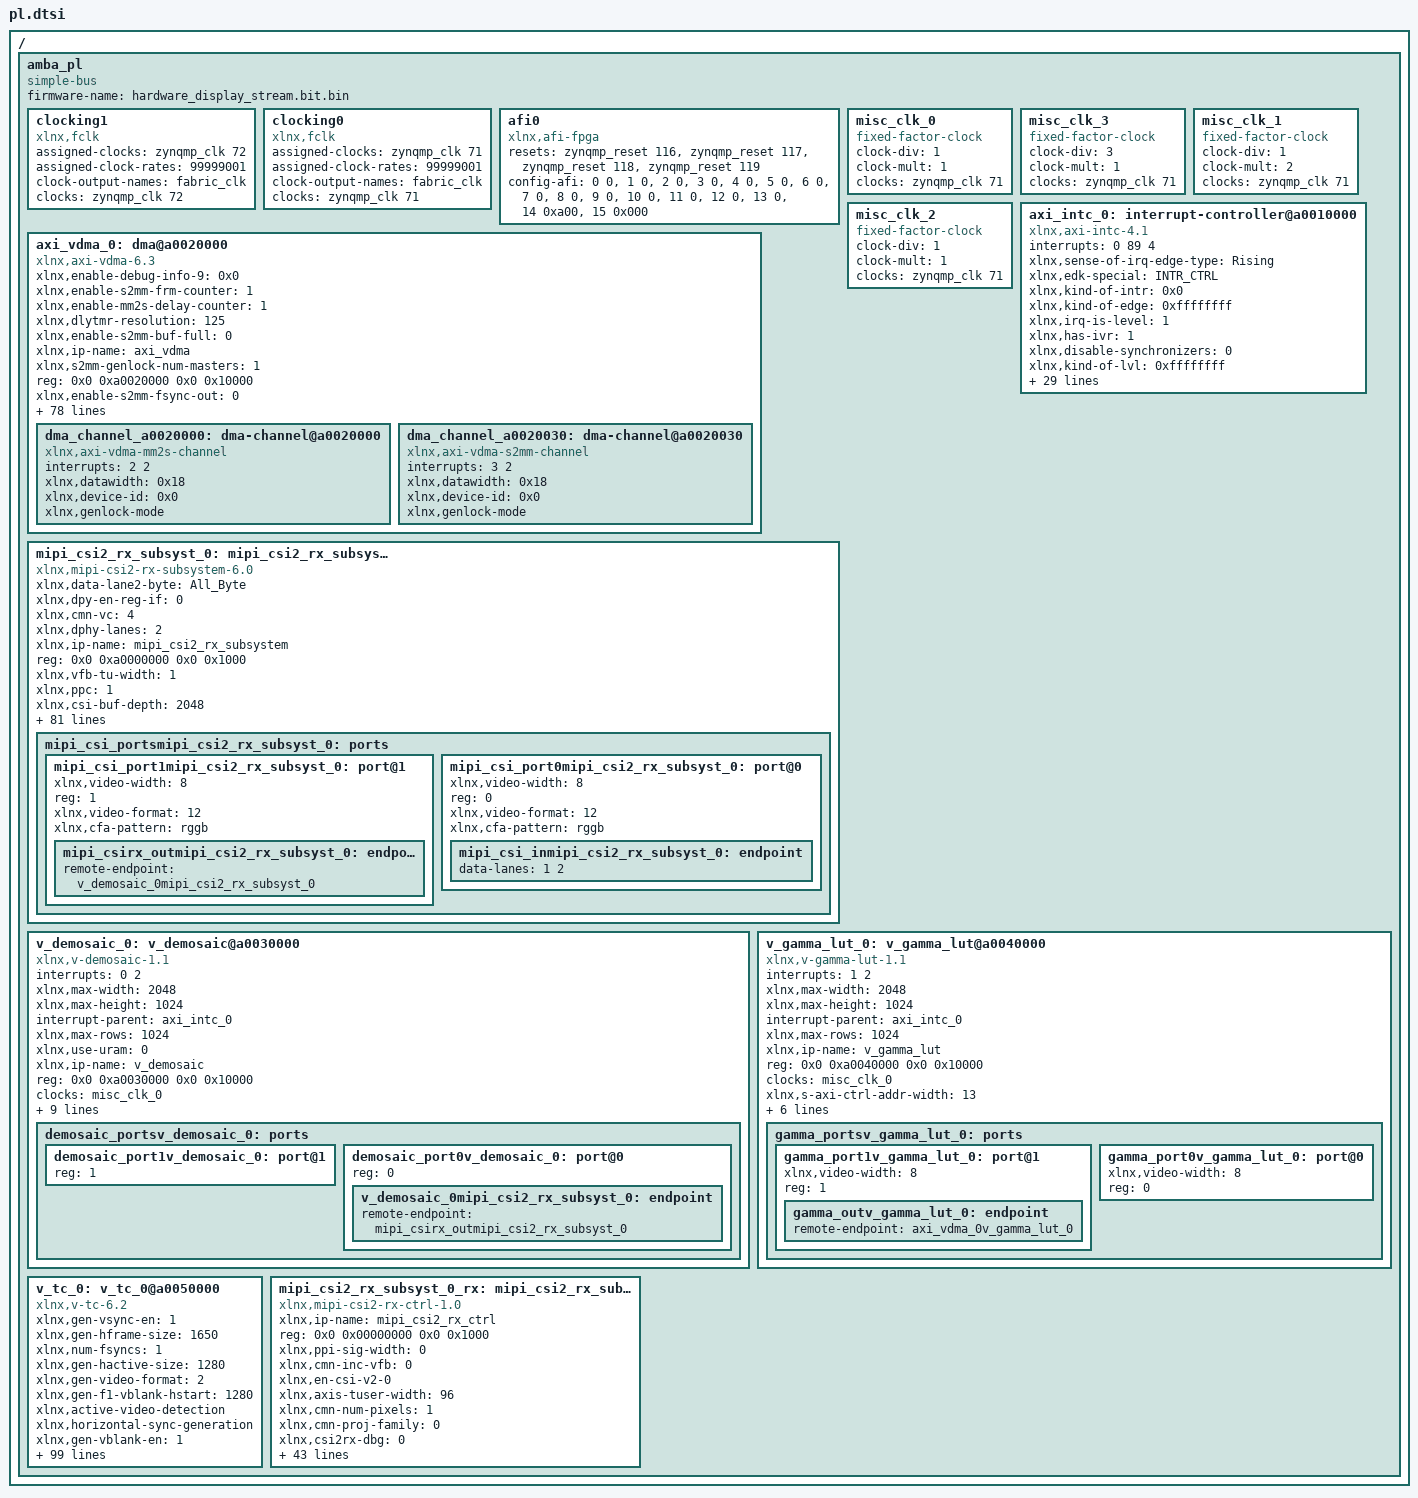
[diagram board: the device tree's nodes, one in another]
/ {
	amba_pl: amba_pl {
		ranges;
		compatible = "simple-bus";
		#address-cells = <2>;
		#size-cells = <2>;
		firmware-name = "hardware_display_stream.bit.bin";
		clocking1: clocking1 {
			compatible = "xlnx,fclk";
			status = "okay";
			assigned-clocks = <&zynqmp_clk 72>;
			assigned-clock-rates = <99999001>;
			#clock-cells = <0>;
			clock-output-names = "fabric_clk";
			clocks = <&zynqmp_clk 72>;
		};
		clocking0: clocking0 {
			compatible = "xlnx,fclk";
			status = "okay";
			assigned-clocks = <&zynqmp_clk 71>;
			assigned-clock-rates = <99999001>;
			#clock-cells = <0>;
			clock-output-names = "fabric_clk";
			clocks = <&zynqmp_clk 71>;
		};
		afi0: afi0 {
			status = "okay";
			compatible = "xlnx,afi-fpga";
			resets = <&zynqmp_reset 116>, <&zynqmp_reset 117>, <&zynqmp_reset 118>, <&zynqmp_reset 119>;
			config-afi = < 0 0>, <1 0>, <2 0>, <3 0>, <4 0>, <5 0>, <6 0>, <7 0>, <8 0>, <9 0>, <10 0>, <11 0>, <12 0>, <13 0>, <14 0xa00>, <15 0x000>;
		};
		misc_clk_0: misc_clk_0 {
			clock-div = <1>;
			compatible = "fixed-factor-clock";
			clock-mult = <1>;
			clocks = <&zynqmp_clk 71>;
			#clock-cells = <0>;
		};
		misc_clk_3: misc_clk_3 {
			clock-div = <3>;
			compatible = "fixed-factor-clock";
			clock-mult = <1>;
			clocks = <&zynqmp_clk 71>;
			#clock-cells = <0>;
		};
		misc_clk_1: misc_clk_1 {
			clock-div = <1>;
			compatible = "fixed-factor-clock";
			clock-mult = <2>;
			clocks = <&zynqmp_clk 71>;
			#clock-cells = <0>;
		};
		misc_clk_2: misc_clk_2 {
			clock-div = <1>;
			compatible = "fixed-factor-clock";
			clock-mult = <1>;
			clocks = <&zynqmp_clk 71>;
			#clock-cells = <0>;
		};
		axi_intc_0: interrupt-controller@a0010000 {
			#interrupt-cells = <2>;
			interrupts = < 0 89 4 >;
			xlnx,sense-of-irq-edge-type = "Rising";
			xlnx,edk-special = "INTR_CTRL";
			xlnx,kind-of-intr = <0x0>;
			xlnx,kind-of-edge = <0xffffffff>;
			xlnx,irq-is-level = <1>;
			xlnx,has-ivr = <1>;
			compatible = "xlnx,axi-intc-4.1" , "xlnx,xps-intc-1.00.a";
			xlnx,disable-synchronizers = <0>;
			xlnx,kind-of-lvl = <0xffffffff>;
			xlnx,ivar-reset-value = <0x10>;
			xlnx,irq-active = <0x1>;
			interrupt-parent = <&imux>;
			xlnx,en-cascade-mode = <0>;
			xlnx,ip-name = "axi_intc";
			xlnx,has-ilr = <0>;
			reg = <0x0 0xa0010000 0x0 0x10000>;
			xlnx,addr-width = <0x20>;
			clocks = <&misc_clk_0>;
			xlnx,s-axi-aclk-freq-mhz = <0x8f0cba4>;
			xlnx,num-sw-intr = <0>;
			xlnx,irq-connection = <1>;
			xlnx,num-intr-inputs = <0x4>;
			xlnx,has-sie = <1>;
			xlnx,enable-async = <0>;
			xlnx,has-cie = <1>;
			xlnx,num-sync-ff = <2>;
			xlnx,edk-iptype = "PERIPHERAL";
			xlnx,mb-clk-not-connected = <1>;
			xlnx,has-ipr = <1>;
			xlnx,sense-of-irq-level-type = "Active_High";
			xlnx,cascade-master = <0>;
			xlnx,processor-clk-freq-mhz = <100>;
			status = "okay";
			xlnx,is-fast = <0x0>;
			clock-names = "s_axi_aclk";
			xlnx,has-fast = <0>;
			xlnx,ivar-rst-val = <0x10>;
			interrupt-controller;
			interrupt-names = "irq";
			xlnx,async-intr = <0xfffffff0>;
			xlnx,name = "axi_intc_0";
		};
		axi_vdma_0: dma@a0020000 {
			xlnx,enable-debug-info-9 = <0x0>;
			xlnx,enable-s2mm-frm-counter = <1>;
			xlnx,enable-mm2s-delay-counter = <1>;
			xlnx,dlytmr-resolution = <125>;
			xlnx,enable-s2mm-buf-full = <0>;
			xlnx,ip-name = "axi_vdma";
			xlnx,s2mm-genlock-num-masters = <1>;
			reg = <0x0 0xa0020000 0x0 0x10000>;
			xlnx,enable-s2mm-fsync-out = <0>;
			xlnx,use-mm2s-fsync = <0>;
			xlnx,s2mm-linebuffer-thresh = <4>;
			xlnx,enable-mm2s-frm-counter = <1>;
			xlnx,m-axis-mm2s-tdata-width = <24>;
			xlnx,enable-all = <0>;
			xlnx,dynamic-resolution = <1>;
			xlnx,enable-s2mm-rst-out = <0>;
			interrupt-names = "mm2s_introut" , "s2mm_introut";
			xlnx,s2mm-sof-enable = <0x1>;
			xlnx,mm2s-genlock-num-masters = <1>;
			xlnx,enable-mm2s-fsync-out = <0>;
			xlnx,mm2s-linebuffer-thresh = <4>;
			compatible = "xlnx,axi-vdma-6.3" , "xlnx,axi-vdma-1.00.a";
			xlnx,enable-tstvec = <0>;
			interrupt-parent = <&axi_intc_0>;
			xlnx,s2mm-max-burst-length = <8>;
			xlnx,enable-mm2s-rst-out = <0>;
			xlnx,mm2s-sof-enable = <1>;
			xlnx,include-s2mm-dre = <0x0>;
			xlnx,enable-s2mm-frmstr-reg = <0>;
			xlnx,m-axi-s2mm-data-width = <64>;
			xlnx,enable-s2mm-sts-reg = <0>;
			xlnx,mm2s-max-burst-length = <8>;
			status = "okay";
			xlnx,include-mm2s-dre = <0x0>;
			xlnx,name = "axi_vdma_0";
			xlnx,enable-mm2s-frmstr-reg = <0>;
			interrupts = < 2 2 3 2 >;
			xlnx,m-axi-mm2s-data-width = <64>;
			xlnx,flush-on-fsync = <0x1>;
			xlnx,include-s2mm-sf = <1>;
			xlnx,single-interface = <0>;
			xlnx,s2mm-linebuffer-depth = <0x200>;
			xlnx,include-s2mm = <0x1>;
			xlnx,addr-width = <32>;
			clocks = <&misc_clk_0>, <&misc_clk_0>, <&misc_clk_0>, <&misc_clk_0>, <&misc_clk_0>;
			xlnx,s-axis-s2mm-tdata-width = <24>;
			xlnx,enable-debug-info-10 = <0>;
			xlnx,addrwidth = <0x20>;
			xlnx,enable-debug-info-11 = <0>;
			xlnx,edk-iptype = "PERIPHERAL";
			xlnx,enable-debug-info-12 = <0>;
			xlnx,use-fsync = <1>;
			xlnx,s2mm-genlock-repeat-en = <1>;
			xlnx,enable-debug-info-13 = <0x0>;
			xlnx,enable-vert-flip = <0x0>;
			xlnx,include-mm2s-sf = <0>;
			xlnx,enable-debug-info-14 = <0x1>;
			xlnx,include-internal-genlock = <0x1>;
			clock-names = "m_axi_mm2s_aclk" , "m_axi_s2mm_aclk" , "m_axis_mm2s_aclk" , "s_axi_lite_aclk" , "s_axis_s2mm_aclk";
			xlnx,enable-debug-info-15 = <0x1>;
			xlnx,mm2s-linebuffer-depth = <0x200>;
			xlnx,include-mm2s = <0x1>;
			xlnx,s2mm-genlock-mode = <0x2>;
			xlnx,flush-fsync = <0x1>;
			xlnx,select-xpm = <0>;
			xlnx,s2mm-data-width = <0x40>;
			xlnx,num-fstores = <0x4>;
			xlnx,enable-s2mm-param-updt = <0>;
			xlnx,enable-vidparam-reads = <0x1>;
			xlnx,mm2s-genlock-repeat-en = <0>;
			xlnx,prmry-is-aclk-async = <0>;
			xlnx,s2mm-tdata-width = <0x18>;
			#dma-cells = <1>;
			xlnx,enable-vidprmtr-reads = <1>;
			xlnx,mm2s-genlock-mode = <0x3>;
			xlnx,enable-debug-info-0 = <0>;
			xlnx,enable-debug-all = <0x0>;
			xlnx,enable-debug-info-1 = <0x0>;
			xlnx,mm2s-data-width = <0x40>;
			xlnx,enable-debug-info-2 = <0>;
			xlnx,enable-mm2s-param-updt = <0>;
			xlnx,enable-debug-info-3 = <0>;
			xlnx,enable-s2mm-delay-counter = <1>;
			xlnx,enable-debug-info-4 = <0>;
			xlnx,enable-debug-info-5 = <0x0>;
			xlnx,mm2s-tdata-width = <0x18>;
			xlnx,enable-debug-info-6 = <0x1>;
			xlnx,enable-debug-info-7 = <0x1>;
			xlnx,use-s2mm-fsync = <2>;
			xlnx,enable-debug-info-8 = <0>;
			xlnx,enable-mm2s-buf-empty = <0>;
			dma_channel_a0020000: dma-channel@a0020000 {
				interrupts = < 2 2 >;
				xlnx,datawidth = <0x18>;
				xlnx,device-id = <0x0>;
				compatible = "xlnx,axi-vdma-mm2s-channel";
				xlnx,genlock-mode;
			};
			dma_channel_a0020030: dma-channel@a0020030 {
				interrupts = < 3 2 >;
				xlnx,datawidth = <0x18>;
				xlnx,device-id = <0x0>;
				compatible = "xlnx,axi-vdma-s2mm-channel";
				xlnx,genlock-mode;
			};
		};
		mipi_csi2_rx_subsyst_0: mipi_csi2_rx_subsystem@a0000000 {
			xlnx,data-lane2-byte = "All_Byte";
			xlnx,dpy-en-reg-if = <0>;
			xlnx,cmn-vc = <4>;
			xlnx,dphy-lanes = <2>;
			xlnx,ip-name = "mipi_csi2_rx_subsystem";
			reg = <0x0 0xa0000000 0x0 0x1000>;
			xlnx,vfb-tu-width = <1>;
			xlnx,ppc = <1>;
			xlnx,csi-buf-depth = <2048>;
			xlnx,exdes-fmc = "LI-IMX274MIPI-FMC , V1.0 , Single , Sensor";
			xlnx,supportlevel = <1>;
			xlnx,clk-lane-io-loc-name = "IO_L13P_T2L_N0_GC_QBC_66";
			xlnx,max-lanes = <2>;
			xlnx,cmn-inc-iic = <0>;
			xlnx,clk-lane-io-loc = "D7";
			xlnx,esc-timeout = <25600>;
			xlnx,cmn-inc-vfb;
			xlnx,en-csi-v2-0;
			xlnx,axis-tuser-width = <96>;
			compatible = "xlnx,mipi-csi2-rx-subsystem-6.0" , "xlnx,mipi-csi2-rx-subsystem-5.0";
			xlnx,en-active-lanes;
			xlnx,idly-tap = <1>;
			xlnx,cmn-num-pixels = <1>;
			xlnx,cmn-proj-family = <1>;
			xlnx,csi2rx-dbg = <0>;
			xlnx,fifo-rd-en-control;
			xlnx,vfb;
			xlnx,data-lane1-io-loc-name = "IO_L15P_T2L_N4_AD11P_66";
			xlnx,hs-timeout = <65541>;
			xlnx,data-lane3-io-loc-name = "None";
			xlnx,ext-mmcm = <0>;
			xlnx,data-lane1-byte = "All_Byte";
			xlnx,cal-mode = "NONE";
			xlnx,mipi-rx-phy-mode = <1>;
			status = "okay";
			xlnx,data-lane0-io-position = <28>;
			xlnx,exdes-board = "ZCU102";
			xlnx,data-lane2-io-position = <6>;
			xlnx,vc = <4>;
			xlnx,en-vcx = <0>;
			xlnx,name = "mipi_csi2_rx_subsyst_0";
			xlnx,csi-emb-non-img = <0>;
			xlnx,dphyrx-board-interface = "Custom";
			xlnx,data-lane3-io-loc = "None";
			xlnx,hs-settle-ns = <170>;
			clocks = <&misc_clk_1>, <&misc_clk_0>, <&misc_clk_0>;
			xlnx,data-lane2-io-loc = "None";
			xlnx,mipi-slv-int = <0>;
			xlnx,cmn-fifo-rd-en-cntrl;
			xlnx,data-lane3-byte = "All_Byte";
			xlnx,stretch-line-rate = <2500>;
			xlnx,axis-tdest-width = <4>;
			xlnx,phy-mode = "DPHY";
			xlnx,en-csi-v2 = <1>;
			xlnx,edk-iptype = "PERIPHERAL";
			xlnx,init = <100000>;
			xlnx,cmn-pxl-format = <0x2b>;
			xlnx,int-qor-check = <0>;
			clock-names = "dphy_clk_200M" , "lite_aclk" , "video_aclk";
			xlnx,data-lane1-io-loc = "G6";
			xlnx,data-lane0-byte = "All_Byte";
			xlnx,ooc-vid-clk = <0x65b710>;
			csirx-present = <1>;
			xlnx,yuv420-buf-dpth = <128>;
			xlnx,hp-io-bank-selection = <66>;
			xlnx,idly-group-name = "mipi_csi2rx_idly_group";
			xlnx,lprx-disable-extport = <0>;
			csirx-connected = <&mipi_csi2_rx_subsyst_0_rx>;
			xlnx,highaddr = <0xa0000fff>;
			xlnx,cmn-num-lanes = <2>;
			xlnx,exdes-config = "MIPI_Video_Pipe_Camera_to_Display";
			xlnx,exdesboard-version = <2>;
			xlnx,dphy-preset = "CSI2RX_XLNX";
			xlnx,data-lane0-io-loc-name = "IO_L14P_T2L_N2_GC_66";
			xlnx,csi-pxl-format = <0x2b>;
			xlnx,clk-lane-io-position = <26>;
			xlnx,data-lane2-io-loc-name = "None";
			xlnx,data-lane0-io-loc = "E5";
			xlnx,inc-phy;
			xlnx,hs-line-rate = <280>;
			xlnx,dpy-line-rate = <280>;
			xlnx,csi-en-activelanes;
			xlnx,csi-en-crc = <1>;
			xlnx,axis-tdata-width = <32>;
			xlnx,csi-controller-reg-if;
			xlnx,data-lane1-io-position = <30>;
			xlnx,dphy-mode = "SLAVE";
			xlnx,data-lane3-io-position = <8>;
			mipi_csi_portsmipi_csi2_rx_subsyst_0: ports {
				#address-cells = <1>;
				#size-cells = <0>;
				mipi_csi_port1mipi_csi2_rx_subsyst_0: port@1 {
					xlnx,video-width = <8>;
					reg = <1>;
					xlnx,video-format = <12>;
					xlnx,cfa-pattern = "rggb";
					mipi_csirx_outmipi_csi2_rx_subsyst_0: endpoint {
						remote-endpoint = <&v_demosaic_0mipi_csi2_rx_subsyst_0>;
					};
				};
				mipi_csi_port0mipi_csi2_rx_subsyst_0: port@0 {
					xlnx,video-width = <8>;
					reg = <0>;
					xlnx,video-format = <12>;
					xlnx,cfa-pattern = "rggb";
					mipi_csi_inmipi_csi2_rx_subsyst_0: endpoint {
						data-lanes = < 1 2 >;
					};
				};
			};
		};
		v_demosaic_0: v_demosaic@a0030000 {
			interrupts = < 0 2 >;
			compatible = "xlnx,v-demosaic-1.1" , "xlnx,v-demosaic";
			xlnx,max-width = <2048>;
			xlnx,max-height = <1024>;
			interrupt-parent = <&axi_intc_0>;
			xlnx,max-rows = <1024>;
			xlnx,use-uram = <0>;
			xlnx,ip-name = "v_demosaic";
			reg = <0x0 0xa0030000 0x0 0x10000>;
			clocks = <&misc_clk_0>;
			xlnx,s-axi-ctrl-addr-width = <6>;
			xlnx,enable-zipper-removal;
			xlnx,samples-per-clock = <1>;
			xlnx,max-data-width = <8>;
			xlnx,edk-iptype = "PERIPHERAL";
			xlnx,max-cols = <2048>;
			status = "okay";
			clock-names = "ap_clk";
			xlnx,algorithm = <0>;
			interrupt-names = "interrupt";
			xlnx,s-axi-ctrl-data-width = <32>;
			xlnx,name = "v_demosaic_0";
			demosaic_portsv_demosaic_0: ports {
				#address-cells = <1>;
				#size-cells = <0>;
				demosaic_port1v_demosaic_0: port@1 {
					reg = <1>;
				};
				demosaic_port0v_demosaic_0: port@0 {
					reg = <0>;
					v_demosaic_0mipi_csi2_rx_subsyst_0: endpoint {
						remote-endpoint = <&mipi_csirx_outmipi_csi2_rx_subsyst_0>;
					};
				};
			};
		};
		v_gamma_lut_0: v_gamma_lut@a0040000 {
			interrupts = < 1 2 >;
			compatible = "xlnx,v-gamma-lut-1.1" , "xlnx,v-gamma-lut";
			xlnx,max-width = <2048>;
			xlnx,max-height = <1024>;
			interrupt-parent = <&axi_intc_0>;
			xlnx,max-rows = <1024>;
			xlnx,ip-name = "v_gamma_lut";
			reg = <0x0 0xa0040000 0x0 0x10000>;
			clocks = <&misc_clk_0>;
			xlnx,s-axi-ctrl-addr-width = <13>;
			xlnx,max-data-width = <8>;
			xlnx,samples-per-clock = <1>;
			xlnx,edk-iptype = "PERIPHERAL";
			xlnx,max-cols = <2048>;
			status = "okay";
			clock-names = "ap_clk";
			interrupt-names = "interrupt";
			xlnx,s-axi-ctrl-data-width = <32>;
			xlnx,name = "v_gamma_lut_0";
			gamma_portsv_gamma_lut_0: ports {
				#address-cells = <1>;
				#size-cells = <0>;
				gamma_port1v_gamma_lut_0: port@1 {
					xlnx,video-width = <8>;
					reg = <1>;
					gamma_outv_gamma_lut_0: endpoint {
						remote-endpoint = <&axi_vdma_0v_gamma_lut_0>;
					};
				};
				gamma_port0v_gamma_lut_0: port@0 {
					xlnx,video-width = <8>;
					reg = <0>;
				};
			};
		};
		v_tc_0: v_tc_0@a0050000 {
			xlnx,gen-vsync-en = <1>;
			xlnx,gen-hframe-size = <1650>;
			xlnx,num-fsyncs = <1>;
			xlnx,gen-hactive-size = <1280>;
			xlnx,gen-video-format = <2>;
			xlnx,gen-f1-vblank-hstart = <1280>;
			xlnx,active-video-detection;
			xlnx,horizontal-sync-generation;
			xlnx,gen-vblank-en = <1>;
			xlnx,gen-avideo-en = <1>;
			xlnx,ip-name = "v_tc";
			xlnx,fsync-hstart10 = <0>;
			xlnx,max-pixels = <4096>;
			xlnx,gen-fieldid-en = <0>;
			reg = <0x0 0xa0050000 0x0 0x10000>;
			xlnx,det-vblank-en = <1>;
			xlnx,fsync-hstart11 = <0>;
			xlnx,fsync-hstart12 = <0>;
			xlnx,gen-interlaced = <0>;
			xlnx,det-avideo-en = <1>;
			xlnx,fsync-hstart13 = <0>;
			xlnx,fsync-hstart14 = <0>;
			xlnx,gen-f0-vblank-hend = <1280>;
			xlnx,fsync-hstart15 = <0>;
			xlnx,det-hsync-en = <1>;
			xlnx,enable-generation;
			xlnx,gen-avideo-polarity = <1>;
			xlnx,max-lines-per-frame = <4096>;
			xlnx,has-axi4-lite = <1>;
			compatible = "xlnx,v-tc-6.2" , "xlnx,v-tc-6.1" , "xlnx,bridge-v-tc-6.1";
			xlnx,max-clocks-per-line = <4096>;
			xlnx,gen-f0-vframe-size = <750>;
			xlnx,gen-f0-vblank-hstart = <1280>;
			xlnx,max-lines = <4096>;
			xlnx,gen-f0-vsync-vstart = <724>;
			xlnx,horizontal-blank-generation;
			xlnx,gen-hsync-end = <1430>;
			xlnx,gen-f0-vsync-hstart = <1280>;
			xlnx,gen-f1-vsync-hend = <1280>;
			xlnx,vertical-blank-detection;
			xlnx,gen-vsync-polarity = <1>;
			xlnx,fsync-vstart0 = <0>;
			xlnx,gen-hsync-polarity = <1>;
			xlnx,fsync-vstart1 = <0>;
			status = "okay";
			xlnx,fsync-vstart2 = <0>;
			xlnx,gen-hsync-start = <1390>;
			xlnx,gen-f0-vsync-vend = <729>;
			xlnx,fsync-vstart3 = <0>;
			xlnx,vertical-sync-detection;
			xlnx,frame-syncs = <1>;
			xlnx,fsync-vstart4 = <0>;
			xlnx,gen-vactive-size = <720>;
			xlnx,name = "v_tc_0";
			xlnx,fsync-vstart5 = <0>;
			xlnx,gen-achroma-en = <0>;
			xlnx,fsync-vstart6 = <0>;
			xlnx,det-fieldid-en = <0>;
			xlnx,fsync-vstart7 = <0>;
			xlnx,gen-hsync-en = <1>;
			xlnx,fsync-vstart8 = <0>;
			xlnx,fsync-vstart10 = <0>;
			xlnx,fsync-vstart9 = <0>;
			xlnx,fsync-vstart11 = <0>;
			xlnx,arbitrary-res-en = <0>;
			xlnx,fsync-vstart12 = <0>;
			xlnx,fsync-vstart13 = <0>;
			clocks = <&misc_clk_2>, <&misc_clk_0>;
			xlnx,fsync-vstart14 = <0>;
			xlnx,fsync-vstart15 = <0>;
			xlnx,gen-cparity = <0>;
			xlnx,edk-iptype = "PERIPHERAL";
			xlnx,vertical-sync-generation;
			xlnx,gen-f1-vblank-hend = <1280>;
			xlnx,det-vsync-en = <1>;
			xlnx,gen-vblank-polarity = <1>;
			xlnx,fsync-hstart0 = <0>;
			clock-names = "clk" , "s_axi_aclk";
			xlnx,interlace-en = <0>;
			xlnx,gen-auto-switch = <0>;
			xlnx,fsync-hstart1 = <0>;
			xlnx,fsync-hstart2 = <0>;
			xlnx,active-video-generation;
			xlnx,fsync-hstart3 = <0>;
			xlnx,fsync-hstart4 = <0>;
			xlnx,horizontal-blank-detection;
			xlnx,fsync-hstart5 = <0>;
			xlnx,gen-f1-vframe-size = <750>;
			xlnx,fsync-hstart6 = <0>;
			xlnx,fsync-hstart7 = <0>;
			xlnx,fsync-hstart8 = <0>;
			xlnx,gen-hblank-en = <1>;
			xlnx,fsync-hstart9 = <0>;
			xlnx,horizontal-sync-detection;
			xlnx,gen-f1-vsync-vend = <729>;
			xlnx,detect-en = <0>;
			xlnx,det-hblank-en = <1>;
			xlnx,vid-ppc = <4>;
			xlnx,has-intc-if = <0>;
			xlnx,generate-en = <1>;
			xlnx,gen-achroma-polarity = <1>;
			xlnx,sync-en = <0>;
			xlnx,det-achroma-en = <0>;
			xlnx,generator;
			xlnx,gen-f1-vsync-vstart = <724>;
			xlnx,vertical-blank-generation;
			xlnx,gen-hblank-polarity = <1>;
			xlnx,video-mode = "720p";
			xlnx,gen-fieldid-polarity = <1>;
			xlnx,gen-f1-vsync-hstart = <1280>;
			xlnx,gen-f0-vsync-hend = <1280>;
		};
		mipi_csi2_rx_subsyst_0_rx: mipi_csi2_rx_subsyst_0_rx@0 {
			xlnx,ip-name = "mipi_csi2_rx_ctrl";
			reg = <0x0 0x00000000 0x0 0x1000>;
			xlnx,ppi-sig-width = <0>;
			xlnx,cmn-inc-vfb = <0>;
			xlnx,en-csi-v2-0;
			xlnx,axis-tuser-width = <96>;
			compatible = "xlnx,mipi-csi2-rx-ctrl-1.0";
			xlnx,cmn-num-pixels = <1>;
			xlnx,cmn-proj-family = <0>;
			xlnx,csi2rx-dbg = <0>;
			xlnx,csi-opt1-regs = <0>;
			xlnx,disable-lite = <0>;
			xlnx,ppi-sync-width = <0>;
			xlnx,csi-filter-userdatatype = <0>;
			xlnx,csi-offload-nonimage = <0>;
			xlnx,csi-vc-off-10 = <11>;
			xlnx,emb-dw = <64>;
			xlnx,csi-vc-off-11 = <12>;
			xlnx,csi-vc-off-12 = <13>;
			status = "okay";
			xlnx,csi-vc-off-13 = <14>;
			xlnx,csi-vc-off-14 = <15>;
			xlnx,ppi-mult = <0>;
			xlnx,name = "mipi_csi2_rx_subsyst_0_rx";
			xlnx,csi-vc-off-0 = <1>;
			xlnx,csi-vc-off-1 = <2>;
			xlnx,csi-vc-off-2 = <3>;
			xlnx,csi-vc-off-3 = <4>;
			xlnx,csi-vc-off-4 = <5>;
			xlnx,csi-lanes = <2>;
			xlnx,csi-vc-off-5 = <6>;
			xlnx,is-hierarchy;
			xlnx,axis-fifo-depth = <2048>;
			xlnx,csi-vc-off-6 = <7>;
			clocks = <&misc_clk_1>, <&misc_clk_3>, <&misc_clk_3>, <&misc_clk_0>, <&misc_clk_0>, <&misc_clk_0>;
			xlnx,axis-fifo-dcnt-width = <11>;
			xlnx,mipi-slv-int = <0>;
			xlnx,csi-vc-off-7 = <8>;
			xlnx,csi-vc-off-8 = <9>;
			xlnx,axis-tdest-width = <4>;
			xlnx,phy-mode = "DPHY";
			xlnx,csi-vc-off-9 = <10>;
			xlnx,edk-iptype = "PERIPHERAL";
			xlnx,cmn-pxl-format = "RAW10";
			xlnx,csi-opt2-crc = <0>;
			clock-names = "core_clk" , "dl0_rxbyteclkhs" , "dl1_rxbyteclkhs" , "m_axis_aclk" , "s_axi_aclk" , "video_aclk";
			xlnx,hp-io-bank-selection = <66>;
			xlnx,csi-opt3-fixedlanes = <0>;
			xlnx,csi-en-vc-support = <1>;
			xlnx,hs-line-rate = <280>;
			xlnx,csi-fixed-vc = <0>;
			xlnx,csi-inv-shutdown = <1>;
			xlnx,axis-tdata-width = <64>;
			xlnx,header-data-width = <32>;
		};
	};
};
